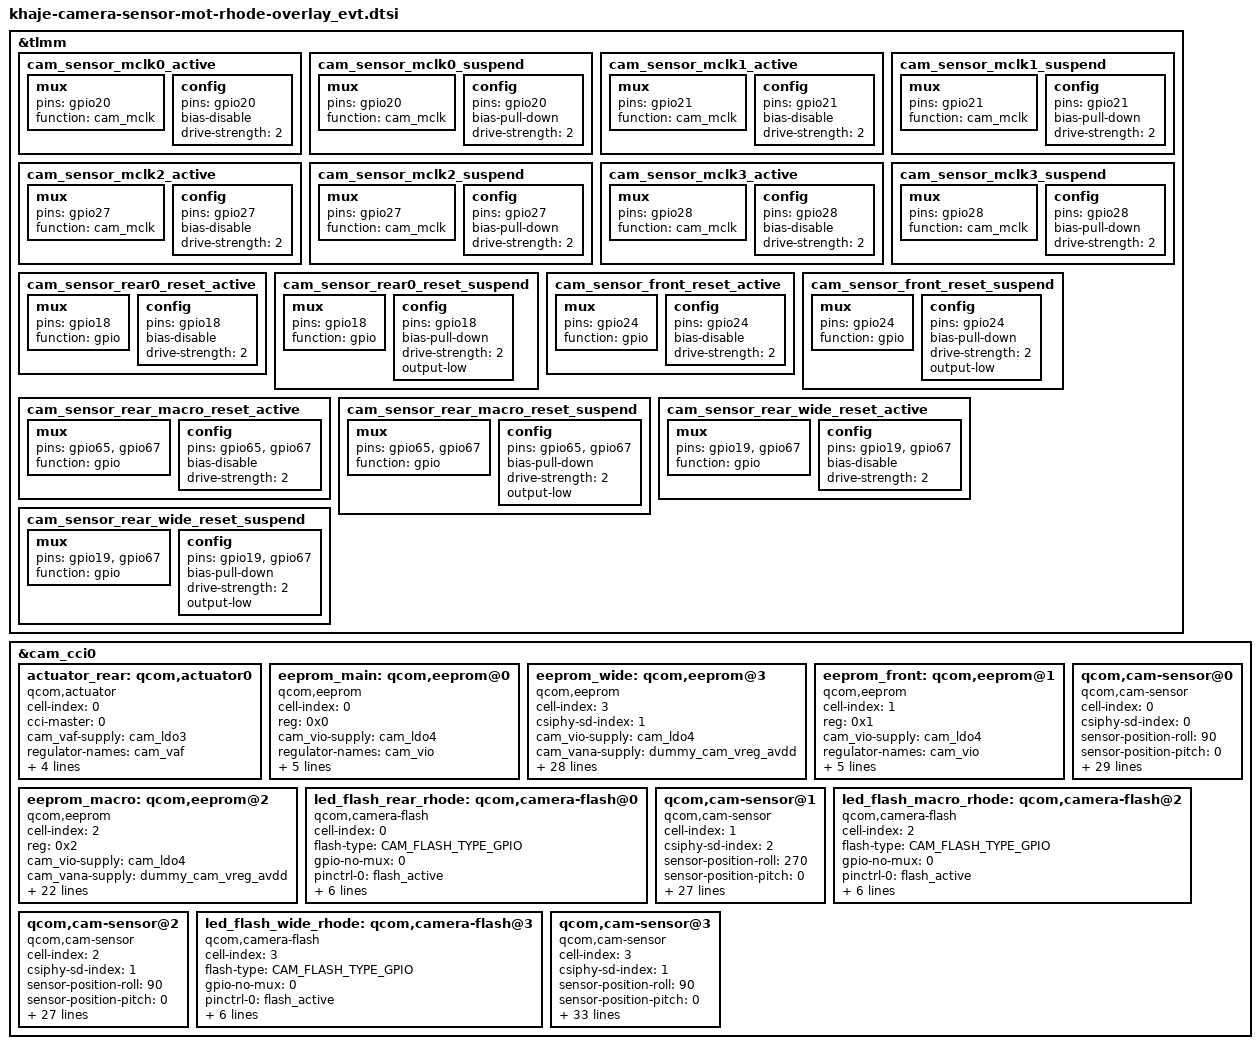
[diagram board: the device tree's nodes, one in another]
#include <dt-bindings/clock/qcom,gcc-khaje.h>
#include <dt-bindings/msm/msm-camera.h>


/delete-node/ &cam_sensor_mclk0_active;
/delete-node/ &cam_sensor_mclk1_active;
/delete-node/ &cam_sensor_mclk2_active;
/delete-node/ &cam_sensor_mclk3_active;
/delete-node/ &cam_sensor_rear0_reset_active;
/delete-node/ &cam_sensor_front_reset_active;
/delete-node/ &cam_sensor_rear_macro_reset_active;
/delete-node/ &cam_sensor_rear_wide_reset_active;
/delete-node/ &cam_sensor_mclk0_suspend;
/delete-node/ &cam_sensor_mclk1_suspend;
/delete-node/ &cam_sensor_mclk2_suspend;
/delete-node/ &cam_sensor_mclk3_suspend;
/delete-node/ &cam_sensor_rear0_reset_suspend;
/delete-node/ &cam_sensor_front_reset_suspend;
/delete-node/ &cam_sensor_rear_macro_reset_suspend;
/delete-node/ &cam_sensor_rear_wide_reset_suspend;
/delete-node/ &led_flash_rear_rhode;
/delete-node/ &led_flash_macro_rhode;
/delete-node/ &led_flash_wide_rhode;

&tlmm {
	cam_sensor_mclk0_active: cam_sensor_mclk0_active {
		/* MCLK 0*/
		mux {
			pins = "gpio20";
			function = "cam_mclk";
		};

		config {
			pins = "gpio20";
			bias-disable;
			drive-strength = <2>;
		};
	};

	cam_sensor_mclk0_suspend: cam_sensor_mclk0_suspend {
		/* MCLK 0*/
		mux {
			pins = "gpio20";
			function = "cam_mclk";
		};

		config {
			pins = "gpio20";
			bias-pull-down;
			drive-strength = <2>;
		};
	};

	cam_sensor_mclk1_active: cam_sensor_mclk1_active {
		mux {
			pins = "gpio21";
			function = "cam_mclk";
		};

		config {
			pins = "gpio21";
			bias-disable; /* No PULL */
			drive-strength = <2>; /* 2 MA */
		};
	};

	cam_sensor_mclk1_suspend: cam_sensor_mclk1_suspend {
		mux {
			pins = "gpio21";
			function = "cam_mclk";
		};

		config {
			pins = "gpio21";
			bias-pull-down;
			drive-strength = <2>; /* 2 MA */
		};
	};

	cam_sensor_mclk2_active: cam_sensor_mclk2_active {
		mux {
			pins = "gpio27";
			function = "cam_mclk";
		};

		config {
			pins = "gpio27";
			bias-disable;
			drive-strength = <2>;
		};
	};

	cam_sensor_mclk2_suspend: cam_sensor_mclk2_suspend {
		mux {
			pins = "gpio27";
			function = "cam_mclk";
		};

		config {
			pins = "gpio27";
			bias-pull-down;
			drive-strength = <2>;
		};
	};

	cam_sensor_mclk3_active: cam_sensor_mclk3_active {
		/* MCLK 3*/
		mux {
			pins = "gpio28";
			function = "cam_mclk";
		};

		config {
			pins = "gpio28";
			bias-disable;
			drive-strength = <2>;
		};
	};

	cam_sensor_mclk3_suspend: cam_sensor_mclk3_suspend {
		/* MCLK 3*/
		mux {
			pins = "gpio28";
			function = "cam_mclk";
		};

		config {
			pins = "gpio28";
			bias-pull-down;
			drive-strength = <2>;
		};
	};

	cam_sensor_rear0_reset_active: cam_sensor_rear0_reset_active {
		mux {
			pins = "gpio18";
			function = "gpio";
		};

		config {
			pins = "gpio18";
			bias-disable; /* No PULL */
			drive-strength = <2>;
		};
	};

	cam_sensor_rear0_reset_suspend: cam_sensor_rear0_reset_suspend {
		mux {
			pins = "gpio18";
			function = "gpio";
		};

		config {
			pins = "gpio18";
			bias-pull-down; /* PULL DOWN */
			drive-strength = <2>;
			output-low;
		};
	};

	cam_sensor_front_reset_active: cam_sensor_front_reset_active {
		mux {
			pins = "gpio24";
			function = "gpio";
		};

		config {
			pins = "gpio24";
			bias-disable; /* No PULL */
			drive-strength = <2>;
		};
	};

	cam_sensor_front_reset_suspend: cam_sensor_front_reset_suspend {
		mux {
			pins = "gpio24";
			function = "gpio";
		};

		config {
			pins = "gpio24";
			bias-pull-down; /* PULL DOWN */
			drive-strength = <2>;
			output-low;
		};
	};

	cam_sensor_rear_macro_reset_active: cam_sensor_rear_macro_reset_active {
		mux {
			pins = "gpio65" ,"gpio67";
			function = "gpio";
		};

		config {
			pins = "gpio65" ,"gpio67";
			bias-disable; /* No PULL */
			drive-strength = <2>; /* 2 MA */
		};
	};

	cam_sensor_rear_macro_reset_suspend: cam_sensor_rear_macro_reset_suspend {
		mux {
			pins = "gpio65" ,"gpio67";
			function = "gpio";
		};

		config {
			pins = "gpio65" ,"gpio67";
			bias-pull-down; /* PULL DOWN */
			drive-strength = <2>; /* 2 MA */
			output-low;
		};
	};


	cam_sensor_rear_wide_reset_active: cam_sensor_rear_wide_reset_active {
		mux {
			pins = "gpio19" ,"gpio67";
			function = "gpio";
		};

		config {
			pins = "gpio19" ,"gpio67";
			bias-disable; /* No PULL */
			drive-strength = <2>; /* 2 MA */
		};
	};

	cam_sensor_rear_wide_reset_suspend: cam_sensor_rear_wide_reset_suspend {
		mux {
			pins = "gpio19" ,"gpio67";
			function = "gpio";
		};

		config {
			pins = "gpio19" ,"gpio67";
			bias-pull-down; /* PULL DOWN */
			drive-strength = <2>; /* 2 MA */
			output-low;
		};
	};
};

/delete-node/ &actuator_rear;
/delete-node/ &eeprom_main;
/delete-node/ &eeprom_wide;
/delete-node/ &eeprom_front;
/delete-node/ &eeprom_macro;

&cam_cci0 {
/delete-node/ qcom,cam-sensor@0;
/delete-node/ qcom,cam-sensor@1;
/delete-node/ qcom,cam-sensor@2;
/delete-node/ qcom,cam-sensor@3;

	actuator_rear: qcom,actuator0 {
		cell-index = <0>;
		compatible = "qcom,actuator";
		cci-master = <0>;
		cam_vaf-supply = <&cam_ldo3>;
		regulator-names = "cam_vaf";
		rgltr-cntrl-support;
		rgltr-min-voltage = <2800000>;
		rgltr-max-voltage = <2805000>;
		rgltr-load-current = <2800000>;
		status = "ok";
	};

	eeprom_main: qcom,eeprom@0 {
		cell-index = <0>;
		reg = <0x0>;
		compatible = "qcom,eeprom";
		cam_vio-supply = <&cam_ldo4>;
		regulator-names = "cam_vio";
		rgltr-cntrl-support;
		rgltr-min-voltage = <1800000>;
		rgltr-max-voltage = <1805000>;
		rgltr-load-current = <3000>;
		cci-master = <0>;
		status = "ok";
	};

	eeprom_wide:qcom,eeprom@3 {
		cell-index = <3>;
		compatible = "qcom,eeprom";
		csiphy-sd-index = <1>;
		cam_vio-supply = <&cam_ldo4>;
		cam_vana-supply = <&dummy_cam_vreg_avdd>;
		cam_vdig-supply = <&dummy_cam_vreg_dvdd>;
		cam_clk-supply = <&gcc_camss_top_gdsc>;
		regulator-names = "cam_vio", "cam_vana", "cam_vdig",
			"cam_clk";
		rgltr-cntrl-support;
		pwm-switch;
		rgltr-min-voltage = <1800000 2800000 1200000 0>;
		rgltr-max-voltage = <1805000 2800000 1200000 0>;
		rgltr-load-current = <120000 80000 1200000 0>;
		gpio-no-mux = <0>;
		pinctrl-names = "cam_default", "cam_suspend";
		pinctrl-0 = <&cam_sensor_mclk1_active
				&cam_sensor_rear_wide_reset_active
				&cam_sensor_csi_mux_sel_active>;
		pinctrl-1 = <&cam_sensor_mclk1_suspend
				&cam_sensor_rear_wide_reset_suspend
				&cam_sensor_csi_mux_sel_suspend>;
		gpios = <&tlmm 21 0>,
			<&tlmm 19 0>,
			<&tlmm 67 0>;
		gpio-reset = <1>;
		gpio-custom1 = <2>;
		gpio-req-tbl-num = <0 1 2>;
		gpio-req-tbl-flags = <1 0 0>;
		gpio-req-tbl-label = "CAMIF_MCLK1",
					"CAM_RESET1",
					"CAM_SWICH_SEL";
		sensor-mode = <0>;
		cci-master = <0>;
		status = "ok";
		clocks = <&gcc GCC_CAMSS_MCLK1_CLK>;
		clock-names = "cam_clk";
		clock-cntl-level = "turbo";
		clock-rates = <24000000>;
	};

	eeprom_front: qcom,eeprom@1 {
		cell-index = <1>;
		reg = <0x1>;
		compatible = "qcom,eeprom";
		cam_vio-supply = <&cam_ldo4>;
		regulator-names = "cam_vio";
		rgltr-cntrl-support;
		rgltr-min-voltage = <1800000>;
		rgltr-max-voltage = <1805000>;
		rgltr-load-current = <3000>;
		cci-master = <1>;
		status = "ok";
	};

	/* macro : gc02m1 */
	eeprom_macro: qcom,eeprom@2 {
		cell-index = <2>;
		reg = <0x2>;
		compatible = "qcom,eeprom";
		cam_vio-supply = <&cam_ldo4>;
		cam_vana-supply = <&dummy_cam_vreg_avdd>;
		cam_clk-supply = <&gcc_camss_top_gdsc>;
		regulator-names = "cam_vio", "cam_vana", "cam_clk";
		rgltr-cntrl-support;
		rgltr-min-voltage = <1800000 2800000 0>;
		rgltr-max-voltage = <1805000 2800000 0>;
		rgltr-load-current = <120000 80000 0>;
		gpio-no-mux = <0>;
		pinctrl-names = "cam_default", "cam_suspend";
		pinctrl-0 = <&cam_sensor_mclk3_active
				&cam_sensor_rear_macro_reset_active>;
		pinctrl-1 = <&cam_sensor_mclk3_suspend
				&cam_sensor_rear_macro_reset_suspend>;
		gpios = <&tlmm 28 0>,
			<&tlmm 65 0>,
			<&tlmm 67 0>;
		gpio-reset = <1>;
		gpio-custom1 = <2>;//sel low for macro,high for wide
		gpio-req-tbl-num = <0 1 2>;
		gpio-req-tbl-flags = <1 0 0>;
		gpio-req-tbl-label = "CAMIF_MCLK3",
					"CAM_REST3",
					"CAM_MIPI_SEL";
		cci-master = <1>;
		status = "ok";
		clocks = <&gcc GCC_CAMSS_MCLK3_CLK>;
		clock-names = "cam_clk";
		clock-cntl-level = "turbo";
		clock-rates = <24000000>;
	};

	led_flash_rear_rhode: qcom,camera-flash@0 {
		cell-index = <0>;
		compatible = "qcom,camera-flash";
		flash-type = <CAM_FLASH_TYPE_GPIO>;
		gpio-no-mux = <0>;
		pinctrl-names = "cam_default", "cam_suspend";
		pinctrl-0 = <&flash_active>;
		pinctrl-1 = <&flash_suspend>;
		gpios = <&tlmm 85 0>;
		gpio-custom1 = <0>;
		gpio-req-tbl-num = <0>;
		gpio-req-tbl-flags = <0>;
		gpio-req-tbl-label = "CUSTOM_GPIO1";
		status = "ok";
	};

	 /* main : JN1*/
	qcom,cam-sensor@0 {
		cell-index = <0>;
		compatible = "qcom,cam-sensor";
		csiphy-sd-index = <0>;
		sensor-position-roll = <90>;
		sensor-position-pitch = <0>;
		sensor-position-yaw = <180>;
		led-flash-src = <&led_flash_rear_rhode>;
		eeprom-src = <&eeprom_main>;
		actuator-src = <&actuator_rear>;
		//cam_vaf-supply = <&cam_ldo3>;
		cam_vio-supply = <&cam_ldo4>;
		cam_vana-supply = <&cam_ldo7>;
		cam_vdig-supply = <&cam_ldo1>;
		cam_clk-supply = <&gcc_camss_top_gdsc>;
		regulator-names ="cam_vio", "cam_vana", "cam_vdig",
			"cam_clk";
		rgltr-cntrl-support;
		pwm-switch;
		rgltr-min-voltage = <1800000 2800000 1056000 0>;
		rgltr-max-voltage = <1805000 2805000 1101000 0>;
		rgltr-load-current = <1800000 2800000 1056000 0>;
		gpio-no-mux = <0>;
		pinctrl-names = "cam_default", "cam_suspend";
		pinctrl-0 = <&cam_sensor_mclk0_active
				&cam_sensor_rear0_reset_active>;
		pinctrl-1 = <&cam_sensor_mclk0_suspend
				&cam_sensor_rear0_reset_suspend>;
		gpios = <&tlmm 20 0>,
			<&tlmm 18 0>;
		gpio-reset = <1>;
		gpio-req-tbl-num = <0 1>;
		gpio-req-tbl-flags = <1 0>;
		gpio-req-tbl-label = "CAMIF_MCLK0",
					"CAM_RESET0";
		cci-master = <0>;
		status = "ok";
		clocks = <&gcc GCC_CAMSS_MCLK0_CLK>;
		clock-names = "cam_clk";
		clock-cntl-level = "turbo";
		clock-rates = <24000000>;
	};

	/*front*/
	 qcom,cam-sensor@1 {
		cell-index = <1>;
		compatible = "qcom,cam-sensor";
		csiphy-sd-index = <2>;
		sensor-position-roll = <270>;
		sensor-position-pitch = <0>;
		sensor-position-yaw = <180>;
		eeprom-src = <&eeprom_front>;
		cam_vio-supply = <&cam_ldo4>;
		cam_vana-supply = <&cam_ldo5>;
		cam_vdig-supply = <&dummy_cam_vreg_dvdd>;
		cam_clk-supply = <&gcc_camss_top_gdsc>;
		regulator-names = "cam_vio", "cam_vana", "cam_vdig",
			"cam_clk";
		rgltr-cntrl-support;
		pwm-switch;
		rgltr-min-voltage = <1800000 2800000 1200000 0>;
		rgltr-max-voltage = <1805000 2805000 1200000 0>;
		rgltr-load-current = <120000 80000 1200000 0>;
		gpio-no-mux = <0>;
		pinctrl-names = "cam_default", "cam_suspend";
		pinctrl-0 = <&cam_sensor_mclk2_active
					&cam_sensor_front_reset_active>;
		pinctrl-1 = <&cam_sensor_mclk2_suspend
					&cam_sensor_front_reset_suspend>;
		gpios = <&tlmm 27 0>,
				<&tlmm 24 0>;
		gpio-reset = <1>;
		gpio-req-tbl-num = <0 1 >;
		gpio-req-tbl-flags = <1 0 >;
		gpio-req-tbl-label = "CAMIF_MCLK2",
					"CAM_RESET2";
		cci-master = <1>;
		status = "ok";
		clocks = <&gcc GCC_CAMSS_MCLK2_CLK>;
		clock-names = "cam_clk";
		clock-cntl-level = "turbo";
		clock-rates = <24000000>;
	};

	led_flash_macro_rhode: qcom,camera-flash@2 {
		cell-index = <2>;
		compatible = "qcom,camera-flash";
		flash-type = <CAM_FLASH_TYPE_GPIO>;
		gpio-no-mux = <0>;
		pinctrl-names = "cam_default", "cam_suspend";
		pinctrl-0 = <&flash_active>;
		pinctrl-1 = <&flash_suspend>;
		gpios = <&tlmm 85 0>;
		gpio-custom1 = <0>;
		gpio-req-tbl-num = <0>;
		gpio-req-tbl-flags = <0>;
		gpio-req-tbl-label = "CUSTOM_GPIO1";
		status = "ok";
	};

	/* macro : gc02m1 */
	qcom,cam-sensor@2 {
		cell-index = <2>;
		compatible = "qcom,cam-sensor";
		csiphy-sd-index = <1>;
		sensor-position-roll = <90>;
		sensor-position-pitch = <0>;
		sensor-position-yaw = <180>;
		eeprom-src = <&eeprom_macro>;
		led-flash-src = <&led_flash_macro_rhode>;
		cam_vio-supply = <&cam_ldo4>;
		cam_vana-supply = <&dummy_cam_vreg_avdd>;
		cam_clk-supply = <&gcc_camss_top_gdsc>;
		regulator-names = "cam_vio", "cam_vana", "cam_clk";
		rgltr-cntrl-support;
		rgltr-min-voltage = <1800000 2800000 0>;
		rgltr-max-voltage = <1805000 2800000 0>;
		rgltr-load-current = <120000 80000 0>;
		gpio-no-mux = <0>;
		pinctrl-names = "cam_default", "cam_suspend";
		pinctrl-0 = <&cam_sensor_mclk3_active
				&cam_sensor_rear_macro_reset_active>;
		pinctrl-1 = <&cam_sensor_mclk3_suspend
				&cam_sensor_rear_macro_reset_suspend>;
		gpios = <&tlmm 28 0>,
			<&tlmm 65 0>,
			<&tlmm 67 0>;
		gpio-reset = <1>;
		gpio-custom1 = <2>;//sel low for macro,high for wide
		gpio-req-tbl-num = <0 1 2>;
		gpio-req-tbl-flags = <1 0 0>;
		gpio-req-tbl-label = "CAMIF_MCLK3",
					"CAM_RESET3",
					"CAM_MIPI_SEL";
		cci-master = <1>;
		status = "ok";
		clocks = <&gcc GCC_CAMSS_MCLK3_CLK>;
		clock-names = "cam_clk";
		clock-cntl-level = "turbo";
		clock-rates = <24000000>;
	};

	led_flash_wide_rhode: qcom,camera-flash@3{
		cell-index = <3>;
		compatible = "qcom,camera-flash";
		flash-type = <CAM_FLASH_TYPE_GPIO>;
		gpio-no-mux = <0>;
		pinctrl-names = "cam_default", "cam_suspend";
		pinctrl-0 = <&flash_active>;
		pinctrl-1 = <&flash_suspend>;
		gpios = <&tlmm 85 0>;
		gpio-custom1 = <0>;
		gpio-req-tbl-num = <0>;
		gpio-req-tbl-flags = <0>;
		gpio-req-tbl-label = "CUSTOM_GPIO1";
		status = "ok";
	};

	/*Rear Aux*/
	qcom,cam-sensor@3 {
		cell-index = <3>;
		compatible = "qcom,cam-sensor";
		csiphy-sd-index = <1>;
		sensor-position-roll = <90>;
		sensor-position-pitch = <0>;
		sensor-position-yaw = <180>;
		led-flash-src = <&led_flash_wide_rhode>;
		eeprom-src = <&eeprom_wide>;
		cam_vio-supply = <&cam_ldo4>;
		cam_vana-supply = <&dummy_cam_vreg_avdd>;
		cam_vdig-supply = <&dummy_cam_vreg_dvdd>;
		cam_clk-supply = <&gcc_camss_top_gdsc>;
		regulator-names = "cam_vio", "cam_vana", "cam_vdig",
			"cam_clk";
		rgltr-cntrl-support;
		pwm-switch;
		rgltr-min-voltage = <1800000 2800000 1200000 0>;
		rgltr-max-voltage = <1805000 2800000 1200000 0>;
		rgltr-load-current = <120000 80000 1200000 0>;
		gpio-no-mux = <0>;
		pinctrl-names = "cam_default", "cam_suspend";
		pinctrl-0 = <&cam_sensor_mclk1_active
				&cam_sensor_rear_wide_reset_active
				&cam_sensor_csi_mux_sel_active>;
		pinctrl-1 = <&cam_sensor_mclk1_suspend
				&cam_sensor_rear_wide_reset_suspend
				&cam_sensor_csi_mux_sel_suspend>;
		gpios = <&tlmm 21 0>,
			<&tlmm 19 0>,
			<&tlmm 67 0>;
		gpio-reset = <1>;
		gpio-custom1 = <2>;
		gpio-req-tbl-num = <0 1 2>;
		gpio-req-tbl-flags = <1 0 0>;
		gpio-req-tbl-label = "CAMIF_MCLK1",
					"CAM_RESET1",
					"CAM_SWICH_SEL";
		sensor-mode = <0>;
		cci-master = <0>;
		status = "ok";
		clocks = <&gcc GCC_CAMSS_MCLK1_CLK>;
		clock-names = "cam_clk";
		clock-cntl-level = "turbo";
		clock-rates = <24000000>;
	};
};
